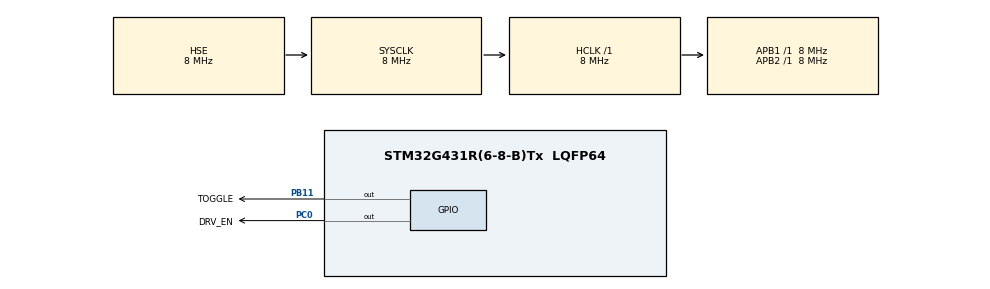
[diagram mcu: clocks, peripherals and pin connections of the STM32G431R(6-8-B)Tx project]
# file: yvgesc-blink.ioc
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Mcu.Family=STM32G4
Mcu.Name=STM32G431R(6-8-B)Tx
Mcu.Package=LQFP64
NVIC.PriorityGroup=NVIC_PRIORITYGROUP_4
PA13.Mode=Serial_Wire
PA13.Signal=SYS_JTMS-SWDIO
PA14.Mode=Serial_Wire
PA14.Signal=SYS_JTCK-SWCLK
PB11.GPIO_Label=TOGGLE
PB11.Signal=GPIO_Output
PC0.GPIO_Label=DRV_EN
PC0.Signal=GPIO_Output
PF0-OSC_IN.Mode=HSE-External-Oscillator
PF0-OSC_IN.Signal=RCC_OSC_IN
PF1-OSC_OUT.Mode=HSE-External-Oscillator
PF1-OSC_OUT.Signal=RCC_OSC_OUT
ProjectManager.HeapSize=0x200
ProjectManager.StackSize=0x400
ProjectManager.TargetToolchain=STM32CubeIDE
RCC.ADC12Freq_Value=8000000
RCC.AHBFreq_Value=8000000
RCC.APB1Freq_Value=8000000
RCC.APB1TimFreq_Value=8000000
RCC.APB2Freq_Value=8000000
RCC.APB2TimFreq_Value=8000000
RCC.CortexFreq_Value=8000000
RCC.EXTERNAL_CLOCK_VALUE=12288000
RCC.HCLKFreq_Value=8000000
RCC.HSI48_VALUE=48000000
RCC.HSI_VALUE=16000000
RCC.LSE_VALUE=32768
RCC.PLLSourceVirtual=RCC_PLLSOURCE_HSE
RCC.SYSCLKFreq_VALUE=8000000
RCC.SYSCLKSource=RCC_SYSCLKSOURCE_HSE
RCC.USBFreq_Value=32000000
RCC.VCOOutputFreq_Value=64000000
VP_SYS_VS_DBSignals.Mode=DisableDeadBatterySignals
board=custom

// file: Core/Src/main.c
/* USER CODE BEGIN Header */
/**
  ******************************************************************************
  * @file           : main.c
  * @brief          : Main program body
  ******************************************************************************
  * @attention
  *
  * Copyright (c) 2026 STMicroelectronics.
  * All rights reserved.
  *
  * This software is licensed under terms that can be found in the LICENSE file
  * in the root directory of this software component.
  * If no LICENSE file comes with this software, it is provided AS-IS.
  *
  ******************************************************************************
  */
/* USER CODE END Header */
#include "main.h"

void SystemClock_Config(void);
static void MX_GPIO_Init(void);

int main(void)
{

  /* MCU Configuration--------------------------------------------------------*/

  /* Reset of all peripherals, Initializes the Flash interface and the Systick. */
  HAL_Init();

  /* Configure the system clock */
  SystemClock_Config();

  /* Initialize all configured peripherals */
  MX_GPIO_Init();

  /* Infinite loop */
  while (1)
  {

    /* USER CODE BEGIN 3 */
	  HAL_GPIO_TogglePin(TOGGLE_GPIO_Port, TOGGLE_Pin);
	  HAL_Delay(2000);
  }
  /* USER CODE END 3 */
}

void SystemClock_Config(void)
{
  RCC_OscInitTypeDef RCC_OscInitStruct = {0};
  RCC_ClkInitTypeDef RCC_ClkInitStruct = {0};

  /** Configure the main internal regulator output voltage
  */
  HAL_PWREx_ControlVoltageScaling(PWR_REGULATOR_VOLTAGE_SCALE1);

  /** Initializes the RCC Oscillators according to the specified parameters
  * in the RCC_OscInitTypeDef structure.
  */
  RCC_OscInitStruct.OscillatorType = RCC_OSCILLATORTYPE_HSE;
  RCC_OscInitStruct.HSEState = RCC_HSE_ON;
  RCC_OscInitStruct.PLL.PLLState = RCC_PLL_NONE;
  if (HAL_RCC_OscConfig(&RCC_OscInitStruct) != HAL_OK)
  {
    Error_Handler();
  }

  /** Initializes the CPU, AHB and APB buses clocks
  */
  RCC_ClkInitStruct.ClockType = RCC_CLOCKTYPE_HCLK|RCC_CLOCKTYPE_SYSCLK
                              |RCC_CLOCKTYPE_PCLK1|RCC_CLOCKTYPE_PCLK2;
  RCC_ClkInitStruct.SYSCLKSource = RCC_SYSCLKSOURCE_HSE;
  RCC_ClkInitStruct.AHBCLKDivider = RCC_SYSCLK_DIV1;
  RCC_ClkInitStruct.APB1CLKDivider = RCC_HCLK_DIV1;
  RCC_ClkInitStruct.APB2CLKDivider = RCC_HCLK_DIV1;

  if (HAL_RCC_ClockConfig(&RCC_ClkInitStruct, FLASH_LATENCY_0) != HAL_OK)
  {
    Error_Handler();
  }
}

static void MX_GPIO_Init(void)
{
  GPIO_InitTypeDef GPIO_InitStruct = {0};

  /* GPIO Ports Clock Enable */
  __HAL_RCC_GPIOF_CLK_ENABLE();
  __HAL_RCC_GPIOC_CLK_ENABLE();
  __HAL_RCC_GPIOB_CLK_ENABLE();
  __HAL_RCC_GPIOA_CLK_ENABLE();

  /*Configure GPIO pin Output Level */
  HAL_GPIO_WritePin(DRV_EN_GPIO_Port, DRV_EN_Pin, GPIO_PIN_RESET);

  /*Configure GPIO pin Output Level */
  HAL_GPIO_WritePin(TOGGLE_GPIO_Port, TOGGLE_Pin, GPIO_PIN_RESET);

  /*Configure GPIO pin : DRV_EN_Pin */
  GPIO_InitStruct.Pin = DRV_EN_Pin;
  GPIO_InitStruct.Mode = GPIO_MODE_OUTPUT_PP;
  GPIO_InitStruct.Pull = GPIO_NOPULL;
  GPIO_InitStruct.Speed = GPIO_SPEED_FREQ_LOW;
  HAL_GPIO_Init(DRV_EN_GPIO_Port, &GPIO_InitStruct);

  /*Configure GPIO pin : TOGGLE_Pin */
  GPIO_InitStruct.Pin = TOGGLE_Pin;
  GPIO_InitStruct.Mode = GPIO_MODE_OUTPUT_PP;
  GPIO_InitStruct.Pull = GPIO_NOPULL;
  GPIO_InitStruct.Speed = GPIO_SPEED_FREQ_LOW;
  HAL_GPIO_Init(TOGGLE_GPIO_Port, &GPIO_InitStruct);

}

void Error_Handler(void)
{
  __disable_irq();
  while (1)
  {
  }
}
